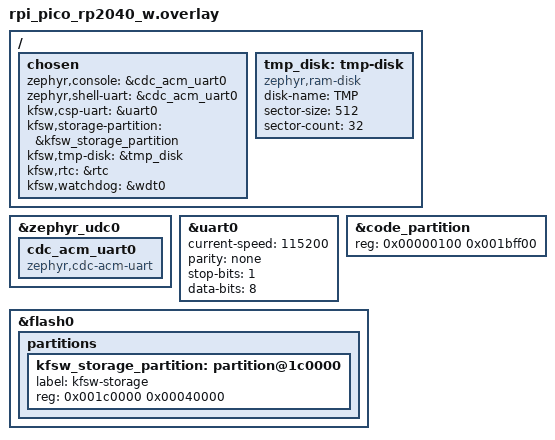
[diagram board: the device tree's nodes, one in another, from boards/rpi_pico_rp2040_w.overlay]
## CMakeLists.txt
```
cmake_minimum_required(VERSION 3.20.0)

# This repository, and the workspace it was fetched into. The workspace is
# found by its west directory rather than assumed to be two levels up, so a git
# worktree of this repository builds its own sources against the one workspace
# that holds Zephyr and the dependency modules.
get_filename_component(KFSW_REPO_ROOT
    "${CMAKE_CURRENT_LIST_DIR}/.."
    ABSOLUTE
)
set(KFSW_WORKSPACE_ROOT "${KFSW_REPO_ROOT}")
while(NOT EXISTS "${KFSW_WORKSPACE_ROOT}/.west")
    get_filename_component(kfsw_parent "${KFSW_WORKSPACE_ROOT}/.." ABSOLUTE)
    if(kfsw_parent STREQUAL KFSW_WORKSPACE_ROOT)
        get_filename_component(KFSW_WORKSPACE_ROOT "${KFSW_REPO_ROOT}/.." ABSOLUTE)
        break()
    endif()
    set(KFSW_WORKSPACE_ROOT "${kfsw_parent}")
endwhile()

# Select the west modules used by this application.
list(APPEND ZEPHYR_EXTRA_MODULES
    "${KFSW_WORKSPACE_ROOT}/kfsw-platform"
    "${KFSW_WORKSPACE_ROOT}/kfsw-comms/third_party/libcsp"
    "${KFSW_WORKSPACE_ROOT}/kfsw-comms"
    "${KFSW_WORKSPACE_ROOT}/kfsw-services"
    "${KFSW_WORKSPACE_ROOT}/kfsw-modules"
)

include("${KFSW_REPO_ROOT}/cmake/release.cmake")
# libcsp options that its Zephyr integration does not take from Kconfig, so
# this is the only place they can be set. Anything the integration does map
# belongs in Kconfig and must not be forced here: KFSW_CSP_HMAC used to be
# contradicted by a forced OFF on this line, and the build worked only because
# the integration happens to run later.
set(CSP_USE_RDP ON CACHE BOOL "" FORCE)
set(CSP_USE_PROMISC OFF CACHE BOOL "" FORCE)

find_package(Zephyr REQUIRED HINTS $ENV{ZEPHYR_BASE})

project(kfsw LANGUAGES C)

if(NOT CONFIG_KFSW_FWU_STANDARD AND NOT CONFIG_KFSW_FWU_LITE)
    message(WARNING
        "No firmware update front end is enabled. Include CONFIG_KFSW_FWU_STANDARD or CONFIG_KFSW_FWU_LITE.")
endif()

if(NOT TARGET kfsw_services)
    message(FATAL_ERROR
        "kfsw-services was not discovered as a Zephyr module")
endif()

if(NOT TARGET kfsw_comms)
    message(FATAL_ERROR
        "kfsw-comms was not discovered as a Zephyr module")
endif()

if(NOT ZEPHYR_KFSW_MODULES_MODULE_DIR)
    message(FATAL_ERROR
        "kfsw-modules was not discovered as a Zephyr module")
endif()

target_sources(app PRIVATE
    src/main.c
)

if(CONFIG_KFSW_HIL_PROBES)
    target_sources(app PRIVATE ../tests/hil/fwu/probes.c)
    zephyr_link_libraries(
        -Wl,--wrap=kfsw_hk_collect
        -Wl,--wrap=kfsw_param_get_by_id
        -Wl,--wrap=kfsw_param_sample_all
        -Wl,--wrap=flash_area_flatten
        -Wl,--wrap=stream_flash_buffered_write
    )
endif()

# Core parameter tables, identifiers 1 to 24. They live in the composition
# layer because kfsw-platform and kfsw-comms sit below the parameter service.
target_sources_ifdef(CONFIG_KFSW_DEBUG_SHELL app PRIVATE
    src/shell/shell_prompt.c
)

# Runs before Zephyr's default handler so a crash leaves its address behind,
# then hands over unchanged.
target_sources_ifdef(CONFIG_KFSW_LASTWORDS app PRIVATE
    src/fatal.c
)

# A native_sim node takes the time from the host.
if(CONFIG_KFSW_CSP AND CONFIG_BOARD_NATIVE_SIM)
    target_sources(app PRIVATE src/clock_host.c)
endif()

if(CONFIG_KFSW_DEBUG_SHELL AND CONFIG_KFSW_COMMAND)
    target_sources(app PRIVATE src/shell/shell_echo.c)
endif()

target_sources_ifdef(CONFIG_KFSW_PARAM app PRIVATE
    src/parameters/board_table.c
    src/parameters/system_table.c
    src/parameters/telemetry_table.c
)

if(CONFIG_KFSW_PARAM AND CONFIG_KFSW_CSP)
    target_sources(app PRIVATE src/parameters/csp_table.c)
endif()

if(CONFIG_KFSW_PARAM AND CONFIG_KFSW_STORAGE)
    target_sources(app PRIVATE src/parameters/storage_table.c)
endif()

if(CONFIG_KFSW_PARAM AND CONFIG_KFSW_WATCHDOG)
    target_sources(app PRIVATE src/parameters/watchdog_table.c)
endif()

target_sources_ifdef(CONFIG_KFSW_COMMAND app PRIVATE
    src/commands/command_definitions.c
)

# The allowlist is the security boundary of remote execution, so it is a
# composition file rather than a service default.
target_sources_ifdef(CONFIG_KFSW_REMEXEC app PRIVATE
    src/remexec/remexec_allowlist.c
)

if(CONFIG_KFSW_PARAM_TEST_DEFINITIONS)
    target_sources(app PRIVATE
        ../tests/support/parameter_definitions.c
    )
    target_include_directories(app PRIVATE
        ../tests/support/include
    )
endif()

if(CONFIG_KFSW_DEBUG_SHELL)
    target_sources(app PRIVATE
        src/shell/shell_system.c
    )

    target_sources_ifdef(CONFIG_KFSW_CSP app PRIVATE
        src/shell/shell_comms.c
        src/shell/shell_csp.c
    )
    if(CONFIG_KFSW_CSP OR CONFIG_KFSW_COMMAND)
        target_sources(app PRIVATE src/shell/shell_remote.c)
    endif()
    target_sources_ifdef(CONFIG_KFSW_CSP_KISS_UART app PRIVATE
        src/shell/shell_uart.c
    )
    target_sources_ifdef(CONFIG_KFSW_CSP_CAN app PRIVATE
        src/shell/shell_can.c
    )
    target_sources_ifdef(CONFIG_KFSW_PARAM app PRIVATE
        src/shell/shell_param.c
    )
    target_sources_ifdef(CONFIG_KFSW_STORAGE app PRIVATE
        src/diagnostics/storage_diagnostics.c
        src/shell/shell_storage.c
    )
    target_sources_ifdef(CONFIG_KFSW_FTP app PRIVATE
        src/diagnostics/ftp_diagnostics.c
        src/shell/shell_ftp.c
    )
    target_sources_ifdef(CONFIG_KFSW_COMMAND app PRIVATE
        src/shell/shell_command.c
        src/shell/shell_registry.c
    )
    target_sources_ifdef(CONFIG_KFSW_GNDWDT app PRIVATE
        src/shell/shell_gndwdt.c
    )
    target_sources_ifdef(CONFIG_KFSW_RESMON app PRIVATE
        src/shell/shell_resmon.c
    )
    target_sources_ifdef(CONFIG_KFSW_SCRUB app PRIVATE
        src/shell/shell_scrub.c
    )
    target_sources_ifdef(CONFIG_KFSW_LIMITS app PRIVATE
        src/shell/shell_limits.c
    )
    target_sources_ifdef(CONFIG_KFSW_REMEXEC app PRIVATE
        src/shell/shell_remexec.c
    )
    target_sources_ifdef(CONFIG_KFSW_HK app PRIVATE
        src/shell/shell_hk.c
    )
    target_sources_ifdef(CONFIG_KFSW_FBO app PRIVATE
        src/shell/shell_fbo.c
    )
    target_sources_ifdef(CONFIG_KFSW_EVENT app PRIVATE
        src/shell/shell_event.c
    )
    if(CONFIG_KFSW_JOURNAL AND CONFIG_KFSW_COMMAND)
        target_sources(app PRIVATE src/shell/shell_journal.c)
    endif()
    target_sources_ifdef(CONFIG_KFSW_WATCHDOG app PRIVATE
        src/shell/shell_watchdog.c
    )
    target_sources_ifdef(CONFIG_KFSW_FWU_STANDARD app PRIVATE
        src/shell/shell_fwu.c
    )
    target_sources_ifdef(CONFIG_KFSW_FWU_LITE_CSP app PRIVATE
        src/shell/shell_fwu_lite.c
    )
    # Also where there is no recovery partition: the boot budget is read and
    # written here, and the hosted target carries it without a bootloader.
    if(CONFIG_KFSW_GOLDEN OR (CONFIG_KFSW_BOOT_STORE AND CONFIG_KFSW_PARAM))
        target_sources(app PRIVATE src/shell/shell_golden.c)
    endif()
    target_sources_ifdef(CONFIG_KFSW_HEALTH app PRIVATE
        src/shell/shell_health.c
    )
    target_sources_ifdef(CONFIG_KFSW_TABLE app PRIVATE
        src/shell/shell_table.c
    )
endif()

target_sources_ifdef(CONFIG_KFSW_CSP_LIVENESS app PRIVATE src/csp_liveness.c)

target_sources_ifdef(CONFIG_KFSW_HK app PRIVATE src/hk_entries.c)

target_include_directories(app PRIVATE src)

# The health slot list is read by kfsw-services, so its path has to reach every
# library and not only the application.
zephyr_include_directories(include)

target_link_libraries(app PRIVATE
    kfsw::platform
    kfsw::services
    kfsw::comms
)

if(CONFIG_KFSW_RADIO_UHF)
    if(NOT TARGET kfsw_radio_uhf)
        message(FATAL_ERROR
            "radio-uhf was enabled but kfsw-modules did not provide its target")
    endif()
    target_link_libraries(app PRIVATE kfsw::radio_uhf)
endif()

if(CONFIG_KFSW_BUTTON_TEST)
    if(NOT TARGET kfsw_button_test)
        message(FATAL_ERROR
            "button_test was enabled but kfsw-modules did not provide its target")
    endif()
    target_link_libraries(app PRIVATE kfsw::button_test)
endif()

if(CONFIG_KFSW_TEMPERATURE_SENSOR_EXAMPLE)
    if(NOT TARGET kfsw_temperature_sensor_example)
        message(FATAL_ERROR
            "the temperature example was enabled but kfsw-modules did not provide its target")
    endif()
    target_link_libraries(app PRIVATE kfsw::temperature_sensor_example)
endif()
```

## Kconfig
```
mainmenu "K-FSW Configuration"

menu "K-FSW application"

config KFSW_ROLE
	string "K-FSW composition role"
	default "flight"
	help
	  Short operator-visible role for this composition, such as flight or
	  ground. This is identity metadata and does not select behavior.

config KFSW_INSTANCE_NAME
	string "K-FSW instance name"
	default "kfsw"
	help
	  Short operator-visible name for this configured K-FSW instance.

config KFSW_DEBUG_SHELL
	bool "K-FSW debug command shell"
	select SHELL
	select SHELL_MINIMAL
	select SHELL_BACKEND_SERIAL
	select SHELL_TAB
	select SHELL_TAB_AUTOCOMPLETION
	select SHELL_HISTORY
	select SHELL_METAKEYS
	select SHELL_HELP
	select SHELL_HELP_ON_WRONG_ARGUMENT_COUNT
	help
	  Enable the serial debug shell and the K-FSW commands. It also turns
	  on usage help for wrong argument counts, which SHELL_MINIMAL disables.
	  Disable it for release builds without an interactive shell.

config KFSW_PARAM_TEST_DEFINITIONS
	bool "Test-only parameter fixture definitions"
	depends on KFSW_PARAM
	help
	  Link integration-only scalar parameter fixtures. Enable this only in
	  software and physical test configurations; normal application
	  compositions contain no test parameters.

rsource "Kconfig.csp_liveness"

config KFSW_HIL_PROBES
	bool "Bench timing and interrupted-update probes"
	depends on KFSW_DEBUG_SHELL && KFSW_HK && KFSW_PARAM && KFSW_FWU
	depends on TIMER_HAS_64BIT_CYCLE_COUNTER && !SMP
	depends on TRACING_USER && INIT_STACKS && THREAD_STACK_INFO
	depends on THREAD_NAME && THREAD_MONITOR
	help
	  Record wake-to-run latency and service durations. The local hil command
	  can arm a reset between secondary-slot erase pages or write blocks.
	  Only enable this in bench images.

endmenu

# The components this composition names in table 31.
config KFSW_HEALTH_SLOTS
	default y
	depends on KFSW_HEALTH && KFSW_PARAM

config KFSW_HEALTH_SLOTS_HEADER
	default "kfsw/app/health_slots.h"
	depends on KFSW_HEALTH_SLOTS

# libcsp defaults to 16, and the service block 8 to 16 already fills it, so
# there is no room for another port. Both CSP 1 and CSP 2 carry a 6 bit port, so
# 32 still leaves the outgoing source ports libcsp places above the bind limit
# (CSP_PORT_MAX_BIND + 1 + i, for CSP_CONN_MAX connections) inside 63.
config CSP_PORT_MAX_BIND
	default 32

config SHELL_PROMPT_UART
	default "kfsw:~$ " if KFSW_DEBUG_SHELL

# The prompt is recoloured at runtime, which Kconfig strings cannot express.
config SHELL_PROMPT_CHANGE
	default y if KFSW_DEBUG_SHELL

# Room for the prompt and its colour codes. Zephyr's default of 10 only fits
# the text; 40 is the maximum.
config SHELL_PROMPT_BUFF_SIZE
	default 40 if KFSW_DEBUG_SHELL

source "Kconfig.zephyr"

config KFSW_APP_HEALTH_DEADLINE_MS
	int "How long the application thread may go without reporting"
	depends on KFSW_HEALTH
	default 4000
	range 200 60000
	help
	  The application reports four times per deadline, so a normal
	  scheduling delay doesn't look like a stopped thread.
```

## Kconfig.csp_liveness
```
# Shared with tests/unit/app_csp_liveness, which builds the probe without the
# rest of the composition and needs the same defaults and ranges.

config KFSW_CSP_LIVENESS
	bool "Watch the CSP router with health"
	depends on KFSW_HEALTH
	default y
	help
	  The application loop reporting to health only proves the scheduler
	  runs. This carries a packet to this node's own address on a period and
	  reports only when it arrives, so a router or connection pool that has
	  stopped serving stops the watchdog being fed.

if KFSW_CSP_LIVENESS

config KFSW_CSP_LIVENESS_PERIOD_MS
	int "How often the probe runs, in milliseconds"
	default 2000
	range 20 60000

config KFSW_CSP_LIVENESS_TIMEOUT_MS
	int "How long the probe waits for its own reply, in milliseconds"
	default 500
	range 5 10000

config KFSW_CSP_LIVENESS_DEADLINE_MS
	int "Health deadline for the probe, in milliseconds"
	default 8000
	range 100 120000
	help
	  Several periods, so one lost probe on a busy node does not reset it.

endif # KFSW_CSP_LIVENESS
```

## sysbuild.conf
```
# Only used with KFSW_SYSBUILD (the MCUboot composition).
#
# These must be SB_CONFIG_* symbols: sysbuild overrides settings placed in
# app/sysbuild/mcuboot.conf.
SB_CONFIG_BOOTLOADER_MCUBOOT=y

# ECDSA P-256 instead of RSA-2048: smaller signatures and a smaller bootloader.
SB_CONFIG_BOOT_SIGNATURE_TYPE_ECDSA_P256=y

# The signing key is passed at build time. Without it MCUboot uses its public
# development key.
```

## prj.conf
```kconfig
CONFIG_SERIAL=y
CONFIG_CONSOLE=y
CONFIG_UART_CONSOLE=y
CONFIG_PRINTK=y
CONFIG_KFSW_LOG_MIN_LEVEL=1

CONFIG_KFSW_DEBUG_SHELL=y

CONFIG_HWINFO=y

CONFIG_FLASH=y
CONFIG_FLASH_MAP=y
CONFIG_FILE_SYSTEM=y
CONFIG_FILE_SYSTEM_LITTLEFS=y
CONFIG_FILE_SYSTEM_MKFS=y
CONFIG_KFSW_STORAGE=y

CONFIG_ASSERT=y

CONFIG_MAIN_STACK_SIZE=2048
```

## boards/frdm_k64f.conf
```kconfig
# FRDM-K64F runs the debug shell only.
CONFIG_KFSW_CSP=n
CONFIG_KFSW_PARAM=n
CONFIG_KFSW_PARAM_PERSISTENCE=n
CONFIG_KFSW_FTP=n
CONFIG_KFSW_STORAGE=n

CONFIG_FLASH=n
CONFIG_FLASH_MAP=n
CONFIG_FILE_SYSTEM=n
CONFIG_FILE_SYSTEM_LITTLEFS=n
CONFIG_FILE_SYSTEM_MKFS=n

# Zephyr's OpenOCD runner consumes the Intel HEX image on this board.
CONFIG_BUILD_OUTPUT_HEX=y
```

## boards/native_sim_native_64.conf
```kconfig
CONFIG_KFSW_CSP=y
CONFIG_KFSW_LOG_HISTORY=y
CONFIG_KFSW_LOG_REMOTE=y
CONFIG_KFSW_PARAM=y
# No table declares a float; the formatting costs 3.2 KB of flash.
CONFIG_KFSW_PARAM_FLOAT=n
CONFIG_KFSW_PARAM_CSP=y
CONFIG_KFSW_PARAM_PERSISTENCE=y
CONFIG_KFSW_TABLE=y
CONFIG_KFSW_FTP=y
CONFIG_KFSW_CSP_ADDRESS=1
CONFIG_KFSW_CSP_HOSTNAME="kfsw-1"
CONFIG_KFSW_CSP_KISS_UART=y
CONFIG_KFSW_CSP_UART_PEER_ADDRESS=2
# Everything off-node leaves through the serial link.
CONFIG_KFSW_CSP_ROUTE_TABLE="0/0 KISS"

# libcsp's Zephyr USART driver uses a small fixed startup context.
CONFIG_HEAP_MEM_POOL_SIZE=2048
CONFIG_KFSW_COMMAND=y
CONFIG_KFSW_COMMAND_CSP=y
CONFIG_KFSW_COMMAND_RETRY=y
CONFIG_REBOOT=y
CONFIG_KFSW_EVENT=y
CONFIG_KFSW_JOURNAL=y

# Buffer and connection-queue capacity for concurrent CSP services.
CONFIG_CSP_BUFFER_COUNT=32
CONFIG_CSP_CONN_RXQUEUE_LEN=32
CONFIG_CSP_QFIFO_LEN=32

# 10 kHz ticks, as on the NUCLEO. The KISS receive thread polls the PTY once a
# tick, so at native_sim's default 100 Hz every round trip came out in 10 ms steps.
CONFIG_SYS_CLOCK_TICKS_PER_SEC=10000

# libcsp reads the wall clock through POSIX; a native node has the host time.
CONFIG_POSIX_API=y
CONFIG_POSIX_TIMERS=y

# Housekeeping: name a set of values once, then ask for the set.
CONFIG_KFSW_HK=y

# The hosted build includes the sample store so the tests cover it.
CONFIG_KFSW_HK_STORE=y

# Beacons are built in but stay off until a report is given an interval.
CONFIG_KFSW_HK_BEACON=y

# File based operations, so a procedure can be exercised by the software tests.
CONFIG_KFSW_FBO=y

# Ground watchdog: reset unless a valid ground_wtd feed arrives.
CONFIG_KFSW_GNDWDT=y

# native_sim needs this for sys_reboot to actually stop the process.
CONFIG_NATIVE_SIM_REBOOT=y

# Resource monitor: how much stack each thread has left.
CONFIG_KFSW_RESMON=y

# Limits: release a command when a parameter crosses a bound set in limits.txt.
CONFIG_KFSW_LIMITS=y

# Remote shell execution, limited to the allowlist in app/src/remexec.
CONFIG_KFSW_REMEXEC=y

# Firmware update, with both slots readable under /boot through FTP. There is
# no bootloader here, so a completed image is checked but never booted.
CONFIG_MCUBOOT_BOOTUTIL_LIB=y
CONFIG_KFSW_FWU=y
CONFIG_KFSW_BOOT_STORE=y
CONFIG_KFSW_BOOT_BUDGET=y

# RAM scratch volume at /kfsw/tmp (kfsw,tmp-disk in the overlay).
CONFIG_DISK_ACCESS=y
CONFIG_FS_LITTLEFS_BLK_DEV=y

# Opt in to log mirroring on the debug shell with an extra configuration.
CONFIG_KFSW_LOG_SHELL=n
```

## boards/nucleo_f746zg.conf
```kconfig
# A second CSP node for the CAN bench. It carries the shell, CSP and CAN and
# nothing that needs a filesystem, because what it is for is being another
# node on the wire.
CONFIG_KFSW_CSP=y
CONFIG_KFSW_CSP_ADDRESS=3
CONFIG_KFSW_CSP_HOSTNAME="kfsw-3"
CONFIG_KFSW_COMMAND=y
CONFIG_KFSW_COMMAND_CSP=y

# No storage on this board, so everything that lands in a file is out.
CONFIG_KFSW_PARAM_PERSISTENCE=n
CONFIG_KFSW_FTP=n
CONFIG_KFSW_STORAGE=n
CONFIG_KFSW_FBO=n
CONFIG_KFSW_JOURNAL=n
CONFIG_FLASH=n
CONFIG_FLASH_MAP=n
CONFIG_FILE_SYSTEM=n
CONFIG_FILE_SYSTEM_LITTLEFS=n
CONFIG_FILE_SYSTEM_MKFS=n

# Resource monitor: how much stack each thread has left, on real stacks.
CONFIG_KFSW_RESMON=y

# libcsp's CAN interface takes its context from the kernel heap when the
# interface opens, so a node on the bus needs one. It is allocated once at
# startup and never freed.
CONFIG_HEAP_MEM_POOL_SIZE=2048

CONFIG_CSP_BUFFER_COUNT=32
CONFIG_CSP_CONN_RXQUEUE_LEN=32
CONFIG_CSP_QFIFO_LEN=32
CONFIG_SHELL_STACK_SIZE=3072

CONFIG_BUILD_OUTPUT_HEX=y
```

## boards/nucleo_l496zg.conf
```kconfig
CONFIG_USE_DT_CODE_PARTITION=y

CONFIG_KFSW_CSP=y
CONFIG_KFSW_PARAM=y
# No table declares a float; the formatting costs 3.2 KB of flash.
CONFIG_KFSW_PARAM_FLOAT=n
CONFIG_KFSW_PARAM_CSP=y
CONFIG_KFSW_PARAM_PERSISTENCE=y
CONFIG_KFSW_TABLE=y
CONFIG_KFSW_FTP=y
CONFIG_KFSW_CSP_ADDRESS=2
CONFIG_KFSW_CSP_HOSTNAME="kfsw-2"

CONFIG_KFSW_CSP_KISS_UART=y
CONFIG_KFSW_CSP_UART_PEER_ADDRESS=1
# Everything off-node leaves through the serial link.
CONFIG_KFSW_CSP_ROUTE_TABLE="0/0 KISS"

# Avoid overruns in the pinned libcsp polling backend on a physical UART.
CONFIG_UART_INTERRUPT_DRIVEN=y
CONFIG_KFSW_CSP_UART_INTERRUPT_DRIVEN=y

# Reserve a small heap for libcsp runtime allocations.
CONFIG_HEAP_MEM_POOL_SIZE=2048
CONFIG_KFSW_COMMAND=y
CONFIG_KFSW_COMMAND_CSP=y
CONFIG_KFSW_GNDWDT=y
CONFIG_REBOOT=y
CONFIG_KFSW_EVENT=y

# Buffer and connection-queue capacity for concurrent CSP services.
CONFIG_CSP_BUFFER_COUNT=32
CONFIG_CSP_CONN_RXQUEUE_LEN=32
CONFIG_CSP_QFIFO_LEN=32

# The shell prints parameter listings from its own stack, measured at 2208
# bytes, which overflowed the 2048 default. 3072 leaves 864 spare.
CONFIG_SHELL_STACK_SIZE=3072

# Housekeeping: name a set of values once, then ask for the set.
CONFIG_KFSW_HK=y

# Beacons are built in but stay off until a report is given an interval.
CONFIG_KFSW_HK_BEACON=y

# RTC wall clock, so the time survives a reset. A power cycle also needs VBAT.
CONFIG_RTC=y

# Why the node restarted. Without these a reset leaves nothing behind: the note
# survives in retained RAM, and so does the log ring that explains it.
CONFIG_KFSW_LASTWORDS=y
CONFIG_KFSW_LASTWORDS_SUPPLY_WATCH=y
CONFIG_KFSW_LOG_HISTORY=y
CONFIG_KFSW_LOG_REMOTE=y

# The independent watchdog, armed at start. A watchdog that waits for a ground
# command does not cover the hang that happens before the first pass. The STM32
# IWDG cannot be disarmed once started.
CONFIG_WATCHDOG=y
CONFIG_KFSW_WATCHDOG=y
CONFIG_KFSW_WATCHDOG_TIMEOUT_MS=8000
CONFIG_KFSW_WATCHDOG_AUTO_START=y

# Health feeds the watchdog only while every component reports in time.
CONFIG_KFSW_HEALTH=y
CONFIG_KFSW_HEALTH_MAX_COMPONENTS=8
CONFIG_KFSW_HEALTH_INTERVAL_MS=500
CONFIG_KFSW_APP_HEALTH_DEADLINE_MS=4000

# RAM scratch volume at /kfsw/tmp (kfsw,tmp-disk in the overlay).
CONFIG_DISK_ACCESS=y
CONFIG_FS_LITTLEFS_BLK_DEV=y

# Opt in to log mirroring on the debug shell with an extra configuration.
CONFIG_KFSW_LOG_SHELL=n

# Resource monitor: how much stack each thread has left. The host build measures
# pthread stacks and cannot qualify these, so this is where the number counts.
CONFIG_KFSW_RESMON=y

# Limits release their actions through file based operations.
CONFIG_KFSW_FBO=y
CONFIG_KFSW_LIMITS=y

# Read-only shell commands reachable from the ground over CSP, from the
# allowlist in app/src/remexec/remexec_allowlist.c. Capturing output needs a
# second shell instance, measured on this board at 6924 bytes of flash and
# 8832 of RAM, which takes RAM from 84.8 to 88.1 per cent.
CONFIG_KFSW_REMEXEC=y
```

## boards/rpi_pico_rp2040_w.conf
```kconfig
CONFIG_USE_DT_CODE_PARTITION=y

CONFIG_KFSW_CSP=y
CONFIG_KFSW_PARAM=y
CONFIG_KFSW_PARAM_FLOAT=n
CONFIG_KFSW_PARAM_CSP=y
CONFIG_KFSW_PARAM_PERSISTENCE=y
CONFIG_KFSW_TABLE=y
CONFIG_KFSW_FTP=y
CONFIG_KFSW_CSP_ADDRESS=3
CONFIG_KFSW_CSP_HOSTNAME="kfsw-3"
CONFIG_KFSW_CSP_KISS_UART=y
CONFIG_KFSW_CSP_UART_PEER_ADDRESS=1
CONFIG_KFSW_CSP_ROUTE_TABLE="0/0 KISS"
CONFIG_UART_INTERRUPT_DRIVEN=y
CONFIG_KFSW_CSP_UART_INTERRUPT_DRIVEN=y

CONFIG_HEAP_MEM_POOL_SIZE=2048
CONFIG_CSP_BUFFER_COUNT=32
CONFIG_CSP_CONN_RXQUEUE_LEN=32
CONFIG_CSP_QFIFO_LEN=32
CONFIG_SHELL_STACK_SIZE=3072

CONFIG_KFSW_COMMAND=y
CONFIG_KFSW_COMMAND_CSP=y
CONFIG_KFSW_COMMAND_RETRY=y
CONFIG_KFSW_EVENT=y
CONFIG_KFSW_JOURNAL=y
CONFIG_KFSW_HK=y
CONFIG_KFSW_HK_STORE=y
CONFIG_KFSW_HK_BEACON=y
CONFIG_KFSW_LOG_HISTORY=y
CONFIG_KFSW_LOG_REMOTE=y
CONFIG_KFSW_LASTWORDS=y
CONFIG_KFSW_REMEXEC=y
CONFIG_KFSW_FBO=y
CONFIG_KFSW_LIMITS=y
CONFIG_KFSW_RESMON=y
CONFIG_KFSW_GNDWDT=y
CONFIG_REBOOT=y

CONFIG_RTC=y
CONFIG_WATCHDOG=y
CONFIG_KFSW_WATCHDOG=y
CONFIG_KFSW_WATCHDOG_TIMEOUT_MS=8000
CONFIG_KFSW_WATCHDOG_AUTO_START=y
CONFIG_KFSW_HEALTH=y
CONFIG_KFSW_HEALTH_MAX_COMPONENTS=8
CONFIG_KFSW_HEALTH_INTERVAL_MS=500
CONFIG_KFSW_APP_HEALTH_DEADLINE_MS=4000

CONFIG_DISK_ACCESS=y
CONFIG_FS_LITTLEFS_BLK_DEV=y

# Use the standard Zephyr USB device stack helper for a one-cable shell.
CONFIG_USB_DEVICE_STACK_NEXT=y
CONFIG_CDC_ACM_SERIAL_INITIALIZE_AT_BOOT=y
CONFIG_CDC_ACM_SERIAL_PRODUCT_STRING="K-FSW Pico W"
CONFIG_UART_LINE_CTRL=y
CONFIG_SHELL_BACKEND_SERIAL_CHECK_DTR=y
```

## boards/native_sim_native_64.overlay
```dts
&uart1 {
	current-speed = <115200>;
	parity = "none";
	stop-bits = "1";
	data-bits = <8>;
	status = "okay";
};

/ {
	chosen {
		kfsw,csp-uart = &uart1;
		kfsw,storage-partition = &storage_partition;
		/* Always set; it costs nothing when the update service is not built in. */
		kfsw,fwu-partition = &slot1_partition;
		kfsw,tmp-disk = &tmp_disk;
		kfsw,boot-budget-partition = &kfsw_boot_budget_partition;
	};

	/* 32 KB of RAM behind /kfsw/tmp, formatted at every boot. */
	tmp_disk: tmp-disk {
		compatible = "zephyr,ram-disk";
		disk-name = "TMP";
		sector-size = <512>;
		sector-count = <64>;
	};
};

/* The last 8 kB of the unused swap scratch, so that it stays below the storage
 * partition: a test overlay that grows storage must not land on top of it.
 */
&scratch_partition {
	reg = <0x000de000 0x0001c000>;
};

&flash0 {
	partitions {
		kfsw_boot_budget_partition: partition@fa000 {
			label = "kfsw-boot-budget";
			reg = <0x000fa000 0x00002000>;
		};
	};
};

&storage_partition {
	label = "kfsw-storage";
	/* 256 kB, where the NUCLEO has 64, to give the housekeeping file store room.
	 * The simulated flash is 2 MB.
	 */
	reg = <0x000fc000 0x00040000>;
};
```

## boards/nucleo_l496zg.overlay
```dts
/ {
	chosen {
		zephyr,code-partition = &kfsw_app_partition;
		kfsw,csp-uart = &usart3;
		kfsw,storage-partition = &kfsw_storage_partition;
		/* The RTC counter is not cleared by a reset. */
		kfsw,rtc = &rtc;
		/* watchdog0 names the window watchdog. The independent one has a
		 * longer timeout and runs in most low-power states.
		 */
		kfsw,watchdog = &iwdg;
		kfsw,tmp-disk = &tmp_disk;
	};

	/* 32 KB of SRAM2 behind /kfsw/tmp, formatted at every boot. Nothing else
	 * uses SRAM2, and it keeps its contents across a reset, hence the format.
	 */
	tmp_disk: tmp-disk {
		compatible = "zephyr,ram-disk";
		disk-name = "TMP";
		sector-size = <512>;
		sector-count = <64>;
		ram-region = <&sram1>;
	};
};

&iwdg {
	status = "okay";
};

/* Dedicated CSP/KISS UART. The debug shell remains on LPUART1 PG7/PG8. */
&usart3 {
	label = "usart3";
	pinctrl-0 = <&usart3_tx_pd8 &usart3_rx_pd9>;
	pinctrl-names = "default";
	current-speed = <115200>;
	parity = "none";
	stop-bits = "1";
	data-bits = <8>;
	status = "okay";
};

&flash0 {
	partitions {
		compatible = "fixed-partitions";
		#address-cells = <1>;
		#size-cells = <1>;

		kfsw_app_partition: partition@0 {
			label = "kfsw-app";
			reg = <0x00000000 0x000f0000>;
		};

		kfsw_storage_partition: partition@f0000 {
			label = "kfsw-storage";
			reg = <0x000f0000 0x00010000>;
		};
	};
};
```

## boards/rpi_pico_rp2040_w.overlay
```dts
/ {
	chosen {
		zephyr,console = &cdc_acm_uart0;
		zephyr,shell-uart = &cdc_acm_uart0;
		kfsw,csp-uart = &uart0;
		kfsw,storage-partition = &kfsw_storage_partition;
		kfsw,tmp-disk = &tmp_disk;
		kfsw,rtc = &rtc;
		kfsw,watchdog = &wdt0;
	};

	tmp_disk: tmp-disk {
		compatible = "zephyr,ram-disk";
		disk-name = "TMP";
		sector-size = <512>;
		sector-count = <32>;
	};
};

&zephyr_udc0 {
	cdc_acm_uart0: cdc_acm_uart0 {
		compatible = "zephyr,cdc-acm-uart";
	};
};

&uart0 {
	current-speed = <115200>;
	parity = "none";
	stop-bits = "1";
	data-bits = <8>;
};

&code_partition {
	reg = <0x00000100 0x001bff00>;
};

&flash0 {
	partitions {
		kfsw_storage_partition: partition@1c0000 {
			label = "kfsw-storage";
			reg = <0x001c0000 0x00040000>;
		};
	};
};
```

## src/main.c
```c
#include <errno.h>

#include <zephyr/kernel.h>
#include <zephyr/sys/reboot.h>
#include <zephyr/sys/util.h>

#if CONFIG_KFSW_CSP
#include <kfsw/comms/csp.h>
#endif
#if CONFIG_KFSW_CSP_KISS_UART
#include <kfsw/comms/uart.h>
#endif
#if CONFIG_KFSW_STORAGE
#include <kfsw/platform/storage.h>
#endif
#if CONFIG_KFSW_WATCHDOG
#include <kfsw/platform/watchdog.h>
#endif
#if CONFIG_KFSW_RADIO_UHF
#include <kfsw/modules/radio_uhf.h>
#endif
#if CONFIG_KFSW_BUTTON_TEST
#include <kfsw/modules/button_test.h>
#endif
#if CONFIG_KFSW_TEMPERATURE_SENSOR_EXAMPLE
#include <kfsw/modules/temperature_sensor_example.h>
#endif
#if CONFIG_KFSW_FBO
#include <kfsw/services/fbo.h>
#endif
#if CONFIG_KFSW_LASTWORDS
#include <kfsw/platform/lastwords.h>
#endif
#if CONFIG_KFSW_JOURNAL
#include <kfsw/services/journal.h>
#endif
#if CONFIG_KFSW_TABLE
#include <kfsw/services/table.h>
#endif
#include <kfsw/services/boot.h>
#if CONFIG_KFSW_COMMAND
#include <kfsw/services/command.h>

#include "commands/command_definitions.h"
#endif
#if CONFIG_KFSW_CSP_LIVENESS
#include "csp_liveness.h"
#endif
#if CONFIG_KFSW_EVENT
#include <kfsw/services/event.h>
#endif
#if CONFIG_KFSW_GNDWDT
#include <kfsw/services/gndwdt.h>
#endif
#if CONFIG_KFSW_REMEXEC
#include <kfsw/services/remexec.h>

#include "remexec/remexec_allowlist.h"
#endif
#if CONFIG_KFSW_RESMON
#include <kfsw/services/resmon.h>
#endif
#if CONFIG_KFSW_SCRUB
#include <kfsw/services/scrub.h>
#endif
#if CONFIG_KFSW_LIMITS
#include <kfsw/services/limits.h>
#endif
#if CONFIG_KFSW_HK
#include <kfsw/services/hk.h>
#endif
#if CONFIG_KFSW_FTP
#include <kfsw/services/ftp.h>
#endif
#if CONFIG_KFSW_FWU
#include <kfsw/services/fwu.h>
#endif
#if CONFIG_KFSW_FWU_LITE_CSP
#include <kfsw/services/fwu_lite.h>
#endif
#if CONFIG_KFSW_HEALTH
#include <kfsw/services/health.h>
#endif
#define KFSW_LOG_MODULE KFSW_LOG_MODULE_APP
#include <kfsw/services/golden.h>
#include <kfsw/services/log.h>
#if CONFIG_KFSW_LOG_REMOTE
#include <kfsw/services/log_remote.h>
#endif
#if CONFIG_KFSW_PARAM
#include <kfsw/services/parameter.h>
#if CONFIG_KFSW_PARAM_TEST_DEFINITIONS
#include <kfsw/testing/parameter_definitions.h>
#endif

#include "clock_host.h"
#include "parameters/tables.h"
#endif

/* The prompt and echo only need the shell, not the parameter service. */
#if CONFIG_KFSW_DEBUG_SHELL
#include "shell/shell_prompt.h"
#if CONFIG_KFSW_COMMAND
#include "shell/shell_echo.h"
#endif
#endif

int main(void)
{
	uint32_t startup_failures = 0;
#if CONFIG_KFSW_STORAGE || CONFIG_KFSW_PARAM || CONFIG_KFSW_CSP || CONFIG_KFSW_RADIO_UHF ||        \
	CONFIG_KFSW_BUTTON_TEST || CONFIG_KFSW_COMMAND || CONFIG_KFSW_WATCHDOG ||                  \
	CONFIG_KFSW_GNDWDT || CONFIG_KFSW_RESMON || CONFIG_BOOTLOADER_MCUBOOT
	int result;
#endif

#if CONFIG_KFSW_WATCHDOG
	/* Armed before the flash and filesystem work, where a fault would
	 * otherwise stop the node for good: neither the boot budget nor the
	 * ground watchdog can act on a core that has halted. The IWDG cannot be
	 * retimed or stopped once started, so it is armed once, here, and the
	 * keep-alive runs on the system workqueue above this thread and feeds
	 * through a slow start-up on its own. */
	result = kfsw_platform_watchdog_init();
	if (result == -ENODEV) {
		kfsw_log_info("No watchdog device bound; running unguarded");
	} else if (result != 0) {
		startup_failures++;
		kfsw_log_error("Failed to initialize the watchdog: %d", result);
	} else if (IS_ENABLED(CONFIG_KFSW_WATCHDOG_AUTO_START)) {
		result = kfsw_platform_watchdog_start();
		if (result != 0) {
			startup_failures++;
			kfsw_log_error("Failed to start the watchdog: %d", result);
		} else {
			kfsw_log_info("Watchdog armed with a %d ms timeout",
				      CONFIG_KFSW_WATCHDOG_TIMEOUT_MS);
		}
	}
#endif

	kfsw_log_info("K-FSW application starting");

#if CONFIG_KFSW_RADIO_UHF
	struct kfsw_radio_uhf_info radio_info;

	result = kfsw_radio_uhf_get_info(&radio_info);
	if (result != 0) {
		startup_failures++;
		kfsw_log_error("Failed to read UHF radio composition: %d", result);
	} else {
		kfsw_log_info("UHF radio selected: %s; expected serial %u baud",
			      radio_info.implementation, radio_info.expected_serial_baud);
	}
#endif

#if CONFIG_KFSW_STORAGE
	result = kfsw_storage_init();
	if (result == 0) {
		result = kfsw_storage_mount();
	}
	if (result != 0) {
		startup_failures++;
		kfsw_log_error("Failed to mount storage: %d", result);
	} else {
		kfsw_log_info("Storage mounted at %s", KFSW_STORAGE_MOUNT_POINT);
	}
#endif

#if CONFIG_BOOTLOADER_MCUBOOT && CONFIG_MCUBOOT_IMG_MANAGER
	result = kfsw_boot_diagnostics_start();
	if (result != 0) {
		startup_failures++;
		kfsw_log_error("Boot trial diagnostics unavailable: %d", result);
	}
#endif

#if CONFIG_KFSW_BOOT_CONFIRM_AT_START
	result = kfsw_boot_confirm_image();
	if (result != 0) {
		startup_failures++;
		kfsw_log_error("Could not confirm this image: %d", result);
	}
#endif

#if CONFIG_KFSW_STORAGE_TMP
	result = kfsw_storage_tmp_mount();
	if (result != 0) {
		startup_failures++;
		kfsw_log_error("Failed to mount %s: %d", KFSW_STORAGE_TMP_MOUNT_POINT, result);
	}
#endif

#if CONFIG_KFSW_PARAM
	/* Core tables first, then services, then modules, in band order. */
	const struct kfsw_param_definition_set *const parameter_sets[] = {
		&kfsw_board_param_definitions,        &kfsw_system_param_definitions,
		&kfsw_telemetry_param_definitions,
#if CONFIG_KFSW_CSP
		&kfsw_csp_param_definitions,
#endif
#if CONFIG_KFSW_STORAGE
		&kfsw_storage_param_definitions,
#endif
#if CONFIG_KFSW_WATCHDOG
		&kfsw_watchdog_param_definitions,
#endif
#if CONFIG_KFSW_PARAM_TEST_DEFINITIONS
		&kfsw_test_param_definitions,
#endif
		&kfsw_log_param_definitions,          &kfsw_param_param_definitions,
		&kfsw_boot_param_definitions,
#if CONFIG_KFSW_EVENT
		&kfsw_event_param_definitions,
#endif
#if CONFIG_KFSW_GNDWDT
		&kfsw_gndwdt_param_definitions,
#endif
#if CONFIG_KFSW_RESMON
		&kfsw_resmon_param_definitions,
#endif
#if CONFIG_KFSW_SCRUB
		&kfsw_scrub_param_definitions,
#endif
#if CONFIG_KFSW_LIMITS
		&kfsw_limits_param_definitions,
#endif
#if CONFIG_KFSW_HK
		&kfsw_hk_param_definitions,
#endif
#if CONFIG_KFSW_FBO
		&kfsw_fbo_param_definitions,
#endif
#if CONFIG_KFSW_COMMAND
		&kfsw_command_param_definitions,
#endif
#if CONFIG_KFSW_FTP
		&kfsw_ftp_param_definitions,
#endif
#if CONFIG_KFSW_FWU
		&kfsw_fwu_param_definitions,
#endif
#if CONFIG_KFSW_HEALTH
		&kfsw_health_param_definitions,
#endif
#if CONFIG_KFSW_TABLE
		&kfsw_table_param_definitions,
#endif
#if CONFIG_KFSW_REMEXEC
		&kfsw_remexec_param_definitions,
#endif
#if CONFIG_KFSW_RADIO_UHF
		&kfsw_radio_uhf_param_definitions,
#endif
#if CONFIG_KFSW_BUTTON_TEST
		&kfsw_button_test_param_definitions,
#endif
#if CONFIG_KFSW_TEMPERATURE_SENSOR_EXAMPLE
		&kfsw_temp_example_param_definitions,
#endif
	};

	result = kfsw_param_init(parameter_sets, ARRAY_SIZE(parameter_sets));

	if (result != 0) {
		startup_failures++;
		kfsw_log_error("Failed to initialize parameters: %d", result);
	} else {
		kfsw_log_info("Parameter table initialized");
#if CONFIG_KFSW_PARAM_PERSISTENCE
		bool had_snapshot;

		result = kfsw_param_persist_load();
		had_snapshot = (result == 0);

		if (result == -ENOENT) {
			kfsw_log_info("No parameter snapshot; using compiled defaults");
		} else if (result != 0) {
			startup_failures++;
			kfsw_log_error("Parameter snapshot restore failed (%d); using defaults",
				       result);
		} else {
			kfsw_log_info("Persistent parameters restored");
		}
#endif
		/* Apply restored settings before starting network services.
		 */
		/* After the snapshot, so the count continues from the saved value. */
		kfsw_boot_count_restart();
#if CONFIG_KFSW_PARAM_PERSISTENCE
		/* Written back or the count never leaves RAM and every boot reads
		 * the saved value plus one. Only when a snapshot was already there,
		 * so a cleared one stays cleared and the node keeps its defaults.
		 */
		if (had_snapshot) {
			result = kfsw_param_persist_save();
			if (result != 0) {
				startup_failures++;
				kfsw_log_error("Could not record the restart count (%d)", result);
			}
		}
#endif

		if (kfsw_system_boot_delay_ms() != 0U) {
			kfsw_log_info("Delaying service start by %u ms",
				      kfsw_system_boot_delay_ms());
			k_sleep(K_MSEC(kfsw_system_boot_delay_ms()));
		}
	}
#endif

#if CONFIG_KFSW_BUTTON_TEST
	result = kfsw_button_test_init();
	if (result != 0) {
		startup_failures++;
		kfsw_log_error("Failed to initialize button_test: %d", result);
	} else {
		kfsw_log_info("button_test initialized");
	}
#endif

#if CONFIG_KFSW_FBO
	result = kfsw_fbo_init();
	if (result != 0) {
		startup_failures++;
		kfsw_log_error("Failed to initialize file based operations: %d", result);
	}
#endif

#if CONFIG_KFSW_TEMPERATURE_SENSOR_EXAMPLE
	result = kfsw_temp_example_init();
	if (result != 0) {
		startup_failures++;
		kfsw_log_error("Failed to initialize the temperature example: %d", result);
	} else {
		kfsw_log_info("Temperature example initialized");
	}
#endif

#if CONFIG_KFSW_COMMAND
	const struct kfsw_command_definition_set *const command_sets[] = {
		&kfsw_app_command_definitions,
#if CONFIG_KFSW_FBO
		&kfsw_fbo_command_definitions,
#endif
#if CONFIG_KFSW_GNDWDT
		&kfsw_gndwdt_command_definitions,
#endif
#if CONFIG_KFSW_TEMPERATURE_SENSOR_EXAMPLE
		&kfsw_temp_example_command_definitions,
#endif
	};

	result = kfsw_command_init(command_sets, ARRAY_SIZE(command_sets));
	if (result != 0) {
		startup_failures++;
		kfsw_log_error("Failed to initialize commands: %d", result);
	} else {
		kfsw_log_info("Command registry initialized");
	}
#endif

#if CONFIG_KFSW_CSP
	bool csp_started = false;

	/* Set the revision before CSP starts, so csp ident reports this build. */
	kfsw_csp_set_revision(kfsw_boot_get_image_version());

#if CONFIG_KFSW_RADIO_UHF_CRYPTO
	result = kfsw_radio_uhf_crypto_init();
	if (result != 0) {
		startup_failures++;
		kfsw_log_error("Radio protection initialization: %d", result);
	}
#endif

	result = kfsw_csp_init();

	if (result != 0) {
		startup_failures++;
		kfsw_log_error("Failed to initialize CSP: %d", result);
	} else {
		kfsw_log_info("CSP initialized as node %d", CONFIG_KFSW_CSP_ADDRESS);

#if CONFIG_KFSW_CSP_KISS_UART
		struct kfsw_uart_info uart_info;

		kfsw_uart_get_info(&uart_info);
		kfsw_log_info("CSP KISS UART initialized on %s at %u baud", uart_info.device_name,
			      uart_info.baudrate);
#endif

#if CONFIG_KFSW_PARAM_CSP
		result = kfsw_param_server_start();
		if (result != 0) {
			startup_failures++;
			kfsw_log_error("Failed to start parameter server: %d", result);
		} else {
			kfsw_log_info("Parameter server started on CSP port %d",
				      CONFIG_KFSW_PARAM_PORT);
		}
#endif

		result = kfsw_csp_start();
		if (result != 0) {
			startup_failures++;
			kfsw_log_error("Failed to start CSP router: %d", result);
		} else {
			csp_started = true;
			kfsw_log_info("CSP router started");
#if CONFIG_KFSW_RADIO_UHF_CRYPTO
			(void)kfsw_radio_uhf_crypto_connect();
#endif
#if CONFIG_KFSW_CSP_KISS_UART
			kfsw_log_info("CSP UART interface started");
#endif
		}
	}

#if CONFIG_KFSW_LOG_REMOTE
	if (csp_started) {
		result = kfsw_log_remote_server_start();
		if (result != 0) {
			startup_failures++;
			kfsw_log_error("Failed to start the remote log server: %d", result);
		}
	}
#endif

#if CONFIG_KFSW_FWU_FILES
	result = kfsw_fwu_files_mount();
	if (result != 0) {
		startup_failures++;
		kfsw_log_error("Failed to mount firmware slots: %d", result);
	}
#endif

#if CONFIG_KFSW_FTP
	if (csp_started) {
		result = kfsw_ftp_init();
		if (result == 0) {
			result = kfsw_ftp_start();
		}
		if (result != 0) {
			startup_failures++;
			kfsw_log_error("Failed to start FTP service: %d", result);
		} else {
			kfsw_log_info("FTP service started on CSP port %d",
				      CONFIG_KFSW_FTP_CSP_PORT);
		}
	}
#endif

#if CONFIG_KFSW_FWU_LITE_CSP
	if (csp_started) {
		result = kfsw_fwu_lite_server_start();
		if (result != 0) {
			startup_failures++;
			kfsw_log_error("Failed to start the firmware upload server: %d", result);
		} else {
			kfsw_log_info("Firmware upload server started on CSP port %d",
				      CONFIG_KFSW_FWU_LITE_CSP_PORT);
		}
	}
#endif

#if CONFIG_KFSW_REMEXEC
	/* The allowlist is adopted whether or not CSP came up: a node that
	 * cannot be reached must still refuse by the same list if it is.
	 */
	result = kfsw_remexec_init(&kfsw_app_remexec_allowlist);
	if (result != 0) {
		startup_failures++;
		kfsw_log_error("Remote execution allowlist refused: %d", result);
	} else if (csp_started) {
		result = kfsw_remexec_server_start();
		if (result != 0) {
			startup_failures++;
			kfsw_log_error("Failed to start the remote execution server: %d", result);
		} else {
			kfsw_log_info("Remote execution server started on CSP port %d",
				      CONFIG_KFSW_REMEXEC_CSP_PORT);
		}
	}
#endif

#if CONFIG_KFSW_COMMAND_CSP
	if (csp_started) {
		result = kfsw_command_server_start();
		if (result != 0) {
			startup_failures++;
			kfsw_log_error("Failed to start command server: %d", result);
		} else {
			kfsw_log_info("Command server started on CSP port %d",
				      CONFIG_KFSW_COMMAND_CSP_PORT);
		}
	}
#endif

#endif

#if CONFIG_KFSW_HK
	/* After the parameter tables and CSP, since definitions name both. */
	result = kfsw_hk_init();
	if (result != 0) {
		startup_failures++;
		kfsw_log_error("Failed to initialize housekeeping: %d", result);
	} else {
		struct kfsw_hk_stats hk_status;

		kfsw_hk_get_stats(&hk_status);
		if (hk_status.last_load_error != 0) {
			startup_failures++;
			kfsw_log_error("HK restore failed (%d); using defaults",
				       hk_status.last_load_error);
		}
		result = kfsw_hk_start();
		if (result != 0) {
			startup_failures++;
			kfsw_log_error("Failed to start housekeeping: %d", result);
		}
#if CONFIG_KFSW_HK_CSP
		if (csp_started) {
			result = kfsw_hk_server_start();
			if (result != 0) {
				startup_failures++;
				kfsw_log_error("Failed to start the housekeeping server: %d",
					       result);
			}
		}
#endif
	}
#endif

#if CONFIG_KFSW_RESMON
	/* After the services have started, so their threads are in the first sweep. */
	result = kfsw_resmon_start();
	if (result != 0) {
		startup_failures++;
		kfsw_log_error("Failed to start the resource monitor: %d", result);
	}
#endif

#if CONFIG_KFSW_SCRUB
	/* After the persisted references are restored, or the first sweep would
	 * read every region as unlearned.
	 */
	result = kfsw_scrub_start();
	if (result != 0) {
		startup_failures++;
		kfsw_log_error("Failed to start the image scrub: %d", result);
	}
#endif

#if CONFIG_KFSW_LIMITS
	/* After the persisted switches are restored and the command registry is
	 * frozen, since a rule is checked against both when it is loaded.
	 */
	result = kfsw_limits_init();
	if (result != 0) {
		startup_failures++;
		kfsw_log_error("Failed to load the limits: %d", result);
	}
#endif

#if CONFIG_KFSW_GNDWDT
	result = kfsw_gndwdt_start();
	if (result != 0) {
		startup_failures++;
		kfsw_log_error("Failed to start the ground watchdog: %d", result);
	}
#endif

#if CONFIG_KFSW_HEALTH
	/* Register the application thread with health supervision.
	 */
	uint8_t health_handle = 0U;
	bool health_watching = false;

	result = kfsw_health_register("app", CONFIG_KFSW_APP_HEALTH_DEADLINE_MS, &health_handle);
	if (result != 0) {
		startup_failures++;
		kfsw_log_error("Failed to register the application for health: %d", result);
	} else {
		health_watching = true;
	}

#if CONFIG_KFSW_CSP_LIVENESS
	result = kfsw_csp_liveness_start();
	if (result != 0) {
		startup_failures++;
		kfsw_log_error("Failed to watch the CSP router for health: %d", result);
	}
#endif

	/* Health takes over feeding, so start it after the watchdog is armed. */
	result = kfsw_health_start();
	if (result != 0) {
		startup_failures++;
		kfsw_log_error("Failed to start health monitoring: %d", result);
	}
#endif

#if CONFIG_KFSW_DEBUG_SHELL
	kfsw_shell_prompt_apply();
#if CONFIG_KFSW_COMMAND
	kfsw_shell_echo_apply();
#endif
#endif

#if CONFIG_KFSW_LASTWORDS
	/* Start supply monitoring. -ENOTSUP means no detector is available. */
	result = kfsw_lastwords_watch_supply();
	if (result == 0) {
		kfsw_log_info("Watching the supply");
	} else if (result != -ENOTSUP) {
		kfsw_log_warning("Supply watch unavailable: %d", result);
	}
#endif

#if CONFIG_KFSW_CSP && CONFIG_BOARD_NATIVE_SIM
	/* After every subsystem is up, because they reset the wall clock. */
	(void)kfsw_clock_from_host();
#endif

#if CONFIG_KFSW_JOURNAL
	result = kfsw_journal_start();
	if (result != 0) {
		startup_failures++;
		kfsw_log_error("Journal unavailable; writer will retry: %d", result);
	}
#endif

	kfsw_log_marker("@SERVICES %s failures=%u", startup_failures == 0U ? "ok" : "degraded",
			startup_failures);
	kfsw_boot_service_start();

	for (;;) {
#if CONFIG_KFSW_HEALTH
		if (health_watching) {
			(void)kfsw_health_report(health_handle);
		}
		/* Read every cycle so a change applies on the next one. */
#if CONFIG_KFSW_PARAM
		k_sleep(K_MSEC(kfsw_system_app_report_ms()));
#else
		k_sleep(K_MSEC(CONFIG_KFSW_APP_HEALTH_DEADLINE_MS / 4U));
#endif
#else
		k_sleep(K_SECONDS(60));
#endif
	}

	return 0;
}
```

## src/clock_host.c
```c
#include <stdint.h>

#include <zephyr/kernel.h>

#include <nsi_timer_model.h>

#include <kfsw/comms/csp.h>
#define KFSW_LOG_MODULE KFSW_LOG_MODULE_CSP
#include <kfsw/services/log.h>

/* A native node takes the time from the host.
 *
 * Runs from main instead of an init hook, because subsystems that start in
 * between reset the wall clock.
 */
int kfsw_clock_from_host(void)
{
	struct kfsw_csp_clock clock;
	uint64_t seconds = 0U;
	uint32_t nanoseconds = 0U;
	int result;

	hwtimer_get_pseudohost_rtc_time(&nanoseconds, &seconds);

	clock.seconds = (int32_t)seconds;
	clock.nanoseconds = nanoseconds;

	if (!kfsw_csp_clock_is_set(&clock)) {
		/* The simulator was started with its clock reset, so leave the time unset. */
		kfsw_log_warning("Host clock unavailable; this node has no time");
		return 0;
	}

	result = kfsw_csp_clock_set(&clock);
	if (result != 0) {
		kfsw_log_warning("Could not take the host clock: %d", result);
	}
	return 0;
}
```

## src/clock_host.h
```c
#ifndef KFSW_APP_CLOCK_HOST_H
#define KFSW_APP_CLOCK_HOST_H

/**
 * @brief Set the wall clock from the host. Only for a native_sim node.
 */
int kfsw_clock_from_host(void);

#endif /* KFSW_APP_CLOCK_HOST_H */
```

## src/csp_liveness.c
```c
#include <errno.h>
#include <stdbool.h>
#include <stdint.h>

#include <zephyr/kernel.h>

#include <kfsw/comms/csp.h>
#include <kfsw/services/health.h>
#define KFSW_LOG_MODULE KFSW_LOG_MODULE_HEALTH
#include <kfsw/services/log.h>

#include "csp_liveness.h"

/*
 * The application loop reporting to health only proves the scheduler runs. A
 * node whose router or connection pool has stopped serving still reports, and
 * the watchdog keeps being fed while the ground cannot reach it.
 *
 * This asks the router to carry a packet to this node's own address. It needs no
 * wire and no peer, and it fails when the machinery an operator depends on has
 * stopped, including when another thread is holding a connection it will never
 * release.
 */

/* The probe is the only reason this file is compiled, so a composition that
 * enables it without a router has nothing to probe. The unit suite replaces
 * the router instead of bringing it up.
 */
BUILD_ASSERT(IS_ENABLED(CONFIG_KFSW_CSP) || IS_ENABLED(CONFIG_ZTEST),
	     "KFSW_CSP_LIVENESS needs KFSW_CSP");

#define LIVENESS_PAYLOAD_SIZE 1U

static uint8_t liveness_handle;
static bool registered;
static uint32_t probes;
static uint32_t failures;

static void liveness_work_handler(struct k_work *work);
static K_WORK_DELAYABLE_DEFINE(liveness_work, liveness_work_handler);

static void liveness_work_handler(struct k_work *work)
{
	struct kfsw_csp_info info;
	uint32_t round_trip_us;
	int result;

	ARG_UNUSED(work);

	kfsw_csp_get_info(&info);
	result = kfsw_csp_ping(info.address, CONFIG_KFSW_CSP_LIVENESS_TIMEOUT_MS,
			       LIVENESS_PAYLOAD_SIZE, &round_trip_us);
	if (probes < UINT32_MAX) {
		probes++;
	}

	if (result == 0) {
		(void)kfsw_health_report(liveness_handle);
	} else {
		if (failures < UINT32_MAX) {
			failures++;
		}
		/* Not reporting is the point: health stops feeding the watchdog
		 * when the deadline passes.
		 */
		kfsw_log_warning("CSP liveness probe failed (%d)", result);
	}

	(void)k_work_reschedule(&liveness_work, K_MSEC(CONFIG_KFSW_CSP_LIVENESS_PERIOD_MS));
}

int kfsw_csp_liveness_start(void)
{
	int result;

	if (registered) {
		return -EALREADY;
	}
	result =
		kfsw_health_register("csp", CONFIG_KFSW_CSP_LIVENESS_DEADLINE_MS, &liveness_handle);
	if (result != 0) {
		return result;
	}
	registered = true;

	/* Reported once up front, so the first period cannot miss the deadline. */
	(void)kfsw_health_report(liveness_handle);
	(void)k_work_reschedule(&liveness_work, K_MSEC(CONFIG_KFSW_CSP_LIVENESS_PERIOD_MS));
	return 0;
}

void kfsw_csp_liveness_get_counters(uint32_t *probe_count, uint32_t *failure_count)
{
	if (probe_count != NULL) {
		*probe_count = probes;
	}
	if (failure_count != NULL) {
		*failure_count = failures;
	}
}
```

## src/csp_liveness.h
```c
#ifndef KFSW_APP_CSP_LIVENESS_H
#define KFSW_APP_CSP_LIVENESS_H

#include <stdint.h>

/** Watch the CSP router with health. Call after the router and health start. */
int kfsw_csp_liveness_start(void);

/** Probes attempted and probes that failed since start. */
void kfsw_csp_liveness_get_counters(uint32_t *probe_count, uint32_t *failure_count);

#endif
```

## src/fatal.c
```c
#include <zephyr/arch/cpu.h>
#include <zephyr/fatal.h>
#include <zephyr/kernel.h>
#include <zephyr/sys/reboot.h>

#include <kfsw/platform/lastwords.h>
#include <kfsw/services/boot.h>

/* Fatal error hook: writes the faulting address into the last words note, then
 * restarts. A halted core waits for the watchdog, and a fault before main() has
 * armed it would wait for good.
 */
void k_sys_fatal_error_handler(unsigned int reason, const struct arch_esf *esf)
{
	uint32_t address = 0U;

#if defined(CONFIG_ARM) && !defined(CONFIG_ARM64)
	/* The program counter at the fault, from the stacked exception frame. */
	if (esf != NULL) {
		address = (uint32_t)esf->basic.pc;
	}
#else
	ARG_UNUSED(esf);
#endif

#if CONFIG_KFSW_PARAM
	kfsw_lastwords_write(KFSW_LASTWORDS_FATAL, address, k_uptime_get_32(),
			     kfsw_boot_get_count());
#else
	kfsw_lastwords_write(KFSW_LASTWORDS_FATAL, address, k_uptime_get_32(), 0U);
#endif

#if CONFIG_REBOOT && !CONFIG_ARCH_POSIX
	ARG_UNUSED(reason);
	sys_reboot(SYS_REBOOT_COLD);
#else
	k_fatal_halt(reason);
#endif
}
```

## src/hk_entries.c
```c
#include <ctype.h>
#include <errno.h>
#include <stdint.h>
#include <stdlib.h>
#include <string.h>

#include <zephyr/sys/util.h>

#include <kfsw/services/parameter.h>

#include "hk_entries.h"

int kfsw_app_hk_parse_entry(const char *text, struct kfsw_hk_entry *entry)
{
	unsigned long parts[3];
	size_t count = 0U;
	const char *cursor = text;

	if ((text == NULL) || (entry == NULL)) {
		return -EINVAL;
	}

	for (;;) {
		char *end;

		if ((count == ARRAY_SIZE(parts)) || !isdigit((unsigned char)*cursor)) {
			return -EINVAL;
		}
		errno = 0;
		parts[count] = strtoul(cursor, &end, 0);
		if ((errno == ERANGE) || (parts[count] > UINT16_MAX)) {
			return -EINVAL;
		}
		count++;
		cursor = end;
		if (*cursor != ':') {
			break;
		}
		cursor++;
	}

	if ((*cursor != '\0') || (count < 2U) || (parts[count - 2U] > UINT8_MAX) ||
	    (parts[count - 1U] > KFSW_PARAM_OFFSET_MAX)) {
		return -EINVAL;
	}

	if (count == 2U) {
		entry->node = KFSW_HK_NODE_LOCAL;
		entry->param_id = KFSW_PARAM_ID(parts[0], parts[1]);
	} else {
		entry->node = (uint16_t)parts[0];
		entry->param_id = KFSW_PARAM_ID(parts[1], parts[2]);
	}
	return 0;
}

int kfsw_app_hk_parse_entries(const char *text, struct kfsw_hk_entry *entries, size_t max,
			      size_t *count)
{
	/* One entry at a time into a local buffer, because the text arrives as
	 * a single const string and strtok would write to it.
	 */
	char token[24];
	const char *cursor = text;
	size_t parsed = 0U;

	if ((text == NULL) || (entries == NULL) || (count == NULL) || (max == 0U)) {
		return -EINVAL;
	}

	while (*cursor != '\0') {
		size_t length = 0U;

		while (*cursor == ' ') {
			cursor++;
		}
		if (*cursor == '\0') {
			break;
		}
		while ((cursor[length] != '\0') && (cursor[length] != ' ')) {
			length++;
		}
		if (length >= sizeof(token)) {
			return -EINVAL;
		}
		if (parsed == max) {
			return -E2BIG;
		}
		memcpy(token, cursor, length);
		token[length] = '\0';
		if (kfsw_app_hk_parse_entry(token, &entries[parsed]) != 0) {
			return -EINVAL;
		}
		parsed++;
		cursor += length;
	}

	if (parsed == 0U) {
		return -EINVAL;
	}
	*count = parsed;
	return 0;
}

int kfsw_app_hk_parse_class(const char **text, uint8_t *retrieval_class)
{
	char *end;
	unsigned long value;

	*retrieval_class = KFSW_HK_CLASS_DEFAULT;
	if (strncmp(*text, "class=", 6U) != 0) {
		return 0;
	}
	value = strtoul(*text + 6U, &end, 0);
	if (end == *text + 6U || (*end != ' ' && *end != '\0')) {
		return -EINVAL;
	}
	if (value > KFSW_HK_CLASS_MAX) {
		return -ERANGE;
	}
	*retrieval_class = (uint8_t)value;
	while (*end == ' ') {
		end++;
	}
	*text = end;
	return 0;
}
```

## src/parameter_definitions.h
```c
#ifndef KFSW_APP_PARAMETER_DEFINITIONS_H
#define KFSW_APP_PARAMETER_DEFINITIONS_H

#include <kfsw/services/parameter.h>

extern const struct kfsw_param_definition_set kfsw_app_param_definitions;

#endif
```
